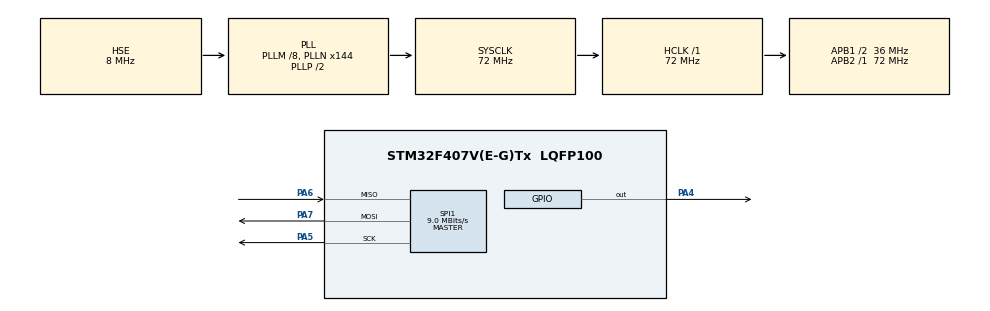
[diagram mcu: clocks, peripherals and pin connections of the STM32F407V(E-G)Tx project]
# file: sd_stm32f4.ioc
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FATFS._MAX_SS=4096
FATFS._USE_LFN=1
Mcu.Family=STM32F4
Mcu.Name=STM32F407V(E-G)Tx
Mcu.Package=LQFP100
NVIC.PriorityGroup=NVIC_PRIORITYGROUP_4
PA4.Signal=GPIO_Output
PA5.Mode=Full_Duplex_Master
PA5.Signal=SPI1_SCK
PA6.Mode=Full_Duplex_Master
PA6.Signal=SPI1_MISO
PA7.Mode=Full_Duplex_Master
PA7.Signal=SPI1_MOSI
PH0-OSC_IN.Mode=HSE-External-Oscillator
PH0-OSC_IN.Signal=RCC_OSC_IN
PH1-OSC_OUT.Mode=HSE-External-Oscillator
PH1-OSC_OUT.Signal=RCC_OSC_OUT
ProjectManager.HeapSize=0x200
ProjectManager.StackSize=0x400
ProjectManager.TargetToolchain=MDK-ARM V5
RCC.48MHZClocksFreq_Value=36000000
RCC.AHBFreq_Value=72000000
RCC.APB1CLKDivider=RCC_HCLK_DIV2
RCC.APB1Freq_Value=36000000
RCC.APB1TimFreq_Value=72000000
RCC.APB2Freq_Value=72000000
RCC.APB2TimFreq_Value=72000000
RCC.CortexFreq_Value=72000000
RCC.HCLKFreq_Value=72000000
RCC.HSE_VALUE=8000000
RCC.HSI_VALUE=16000000
RCC.LSE_VALUE=32768
RCC.PLLM=8
RCC.PLLN=144
RCC.PLLSourceVirtual=RCC_PLLSOURCE_HSE
RCC.SYSCLKFreq_VALUE=72000000
RCC.SYSCLKSource=RCC_SYSCLKSOURCE_PLLCLK
RCC.VCOOutputFreq_Value=144000000
SPI1.BaudRatePrescaler=SPI_BAUDRATEPRESCALER_8
SPI1.CalculateBaudRate=9.0 MBits/s
SPI1.Direction=SPI_DIRECTION_2LINES
SPI1.Mode=SPI_MODE_MASTER
SPI1.VirtualType=VM_MASTER
VP_FATFS_VS_Generic.Mode=User_defined
board=test_sd_stm32f4

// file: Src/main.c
/**
  ******************************************************************************
  * @file           : main.c
  * @brief          : Main program body
  ******************************************************************************
  * This notice applies to any and all portions of this file
  * that are not between comment pairs USER CODE BEGIN and
  * USER CODE END. Other portions of this file, whether
  * inserted by the user or by software development tools
  * are owned by their respective copyright owners.
  *
  * Copyright (c) 2018 STMicroelectronics International N.V.
  * All rights reserved.
  *
  * Redistribution and use in source and binary forms, with or without
  * modification, are permitted, provided that the following conditions are met:
  *
  * 1. Redistribution of source code must retain the above copyright notice,
  *    this list of conditions and the following disclaimer.
  * 2. Redistributions in binary form must reproduce the above copyright notice,
  *    this list of conditions and the following disclaimer in the documentation
  *    and/or other materials provided with the distribution.
  * 3. Neither the name of STMicroelectronics nor the names of other
  *    contributors to this software may be used to endorse or promote products
  *    derived from this software without specific written permission.
  * 4. This software, including modifications and/or derivative works of this
  *    software, must execute solely and exclusively on microcontroller or
  *    microprocessor devices manufactured by or for STMicroelectronics.
  * 5. Redistribution and use of this software other than as permitted under
  *    this license is void and will automatically terminate your rights under
  *    this license.
  *
  * THIS SOFTWARE IS PROVIDED BY STMICROELECTRONICS AND CONTRIBUTORS "AS IS"
  * AND ANY EXPRESS, IMPLIED OR STATUTORY WARRANTIES, INCLUDING, BUT NOT
  * LIMITED TO, THE IMPLIED WARRANTIES OF MERCHANTABILITY, FITNESS FOR A
  * PARTICULAR PURPOSE AND NON-INFRINGEMENT OF THIRD PARTY INTELLECTUAL PROPERTY
  * RIGHTS ARE DISCLAIMED TO THE FULLEST EXTENT PERMITTED BY LAW. IN NO EVENT
  * SHALL STMICROELECTRONICS OR CONTRIBUTORS BE LIABLE FOR ANY DIRECT, INDIRECT,
  * INCIDENTAL, SPECIAL, EXEMPLARY, OR CONSEQUENTIAL DAMAGES (INCLUDING, BUT NOT
  * LIMITED TO, PROCUREMENT OF SUBSTITUTE GOODS OR SERVICES; LOSS OF USE, DATA,
  * OR PROFITS; OR BUSINESS INTERRUPTION) HOWEVER CAUSED AND ON ANY THEORY OF
  * LIABILITY, WHETHER IN CONTRACT, STRICT LIABILITY, OR TORT (INCLUDING
  * NEGLIGENCE OR OTHERWISE) ARISING IN ANY WAY OUT OF THE USE OF THIS SOFTWARE,
  * EVEN IF ADVISED OF THE POSSIBILITY OF SUCH DAMAGE.
  *
  ******************************************************************************
  */
#include "main.h"
#include "stm32f4xx_hal.h"
#include "fatfs.h"

SPI_HandleTypeDef hspi1;

FATFS fs;
FATFS *pfs;
FIL fil;
FRESULT fres;
DWORD fre_clust;
uint32_t total, free1;
char buffer[100];

/* USER CODE BEGIN PV */
/* Private variables ---------------------------------------------------------*/

/* USER CODE END PV */

void SystemClock_Config(void);
static void MX_GPIO_Init(void);
static void MX_SPI1_Init(void);

/* USER CODE BEGIN PFP */
/* Private function prototypes -----------------------------------------------*/

/* USER CODE END PFP */

int main(void)
{

  /* MCU Configuration----------------------------------------------------------*/

  /* Reset of all peripherals, Initializes the Flash interface and the Systick. */
  HAL_Init();

  /* Configure the system clock */
  SystemClock_Config();

  /* Initialize all configured peripherals */
  MX_GPIO_Init();
  MX_FATFS_Init();
  MX_SPI1_Init();
  /* USER CODE BEGIN 2 */
  //HAL_GPIO_WritePin(GPIOA,GPIO_PIN_4,GPIO_PIN_SET);
  //HAL_Delay(10);

	/* USER CODE END 2 */
  /* Mount SD Card */
  if(f_mount(&fs, "", 0) != FR_OK)
    _Error_Handler(__FILE__, __LINE__);

  /* Open file to write */
  if(f_open(&fil, "second.py", FA_OPEN_ALWAYS | FA_READ | FA_WRITE) != FR_OK)
    _Error_Handler(__FILE__, __LINE__);

  /* Check free space */
  if(f_getfree("", &fre_clust, &pfs) != FR_OK)
    _Error_Handler(__FILE__, __LINE__);

  total = (uint32_t)((pfs->n_fatent - 2) * pfs->csize * 0.5);
  free1 = (uint32_t)(fre_clust * pfs->csize * 0.5);

  /* Free space is less than 1kb */
  if(free1 < 1)
    _Error_Handler(__FILE__, __LINE__);

  /* Writing text */
  f_puts("SAKET\n", &fil);
  f_puts("KIRANGE!!!", &fil);

  /* Close file */
  if(f_close(&fil) != FR_OK)
    _Error_Handler(__FILE__, __LINE__);

  /* Open file to read */
  if(f_open(&fil, "second.py", FA_READ) != FR_OK)
    _Error_Handler(__FILE__, __LINE__);

  while(f_gets(buffer, sizeof(buffer), &fil))
  {
    //printf("%s", buffer);
  }

  /* Close file */
  if(f_close(&fil) != FR_OK)
    _Error_Handler(__FILE__, __LINE__);

  /* Unmount SDCARD */
  if(f_mount(NULL, "", 1) != FR_OK)
    _Error_Handler(__FILE__, __LINE__);

  /* Infinite loop */
  while (1)
  {

  }

}

void SystemClock_Config(void)
{

  RCC_OscInitTypeDef RCC_OscInitStruct;
  RCC_ClkInitTypeDef RCC_ClkInitStruct;

    /**Configure the main internal regulator output voltage
    */
  __HAL_RCC_PWR_CLK_ENABLE();

  __HAL_PWR_VOLTAGESCALING_CONFIG(PWR_REGULATOR_VOLTAGE_SCALE1);

    /**Initializes the CPU, AHB and APB busses clocks
    */
  RCC_OscInitStruct.OscillatorType = RCC_OSCILLATORTYPE_HSE;
  RCC_OscInitStruct.HSEState = RCC_HSE_ON;
  RCC_OscInitStruct.PLL.PLLState = RCC_PLL_ON;
  RCC_OscInitStruct.PLL.PLLSource = RCC_PLLSOURCE_HSE;
  RCC_OscInitStruct.PLL.PLLM = 8;
  RCC_OscInitStruct.PLL.PLLN = 144;
  RCC_OscInitStruct.PLL.PLLP = RCC_PLLP_DIV2;
  RCC_OscInitStruct.PLL.PLLQ = 4;
  if (HAL_RCC_OscConfig(&RCC_OscInitStruct) != HAL_OK)
  {
    _Error_Handler(__FILE__, __LINE__);
  }

    /**Initializes the CPU, AHB and APB busses clocks
    */
  RCC_ClkInitStruct.ClockType = RCC_CLOCKTYPE_HCLK|RCC_CLOCKTYPE_SYSCLK
                              |RCC_CLOCKTYPE_PCLK1|RCC_CLOCKTYPE_PCLK2;
  RCC_ClkInitStruct.SYSCLKSource = RCC_SYSCLKSOURCE_PLLCLK;
  RCC_ClkInitStruct.AHBCLKDivider = RCC_SYSCLK_DIV1;
  RCC_ClkInitStruct.APB1CLKDivider = RCC_HCLK_DIV2;
  RCC_ClkInitStruct.APB2CLKDivider = RCC_HCLK_DIV1;

  if (HAL_RCC_ClockConfig(&RCC_ClkInitStruct, FLASH_LATENCY_2) != HAL_OK)
  {
    _Error_Handler(__FILE__, __LINE__);
  }

    /**Configure the Systick interrupt time
    */
  HAL_SYSTICK_Config(HAL_RCC_GetHCLKFreq()/1000);

    /**Configure the Systick
    */
  HAL_SYSTICK_CLKSourceConfig(SYSTICK_CLKSOURCE_HCLK);

  /* SysTick_IRQn interrupt configuration */
  HAL_NVIC_SetPriority(SysTick_IRQn, 0, 0);
}

/* SPI1 init function */
static void MX_SPI1_Init(void)
{

  /* SPI1 parameter configuration*/
  hspi1.Instance = SPI1;
  hspi1.Init.Mode = SPI_MODE_MASTER;
  hspi1.Init.Direction = SPI_DIRECTION_2LINES;
  hspi1.Init.DataSize = SPI_DATASIZE_8BIT;
  hspi1.Init.CLKPolarity = SPI_POLARITY_LOW;
  hspi1.Init.CLKPhase = SPI_PHASE_1EDGE;
  hspi1.Init.NSS = SPI_NSS_SOFT;
  hspi1.Init.BaudRatePrescaler = SPI_BAUDRATEPRESCALER_8;
  hspi1.Init.FirstBit = SPI_FIRSTBIT_MSB;
  hspi1.Init.TIMode = SPI_TIMODE_DISABLE;
  hspi1.Init.CRCCalculation = SPI_CRCCALCULATION_DISABLE;
  hspi1.Init.CRCPolynomial = 10;
  if (HAL_SPI_Init(&hspi1) != HAL_OK)
  {
    _Error_Handler(__FILE__, __LINE__);
  }

}

/** Configure pins as
        * Analog
        * Input
        * Output
        * EVENT_OUT
        * EXTI
*/
static void MX_GPIO_Init(void)
{

  GPIO_InitTypeDef GPIO_InitStruct;

  /* GPIO Ports Clock Enable */
  __HAL_RCC_GPIOH_CLK_ENABLE();
  __HAL_RCC_GPIOA_CLK_ENABLE();

  /*Configure GPIO pin Output Level */
  HAL_GPIO_WritePin(GPIOA, GPIO_PIN_4, GPIO_PIN_SET);

  /*Configure GPIO pin : PA4 */
  GPIO_InitStruct.Pin = GPIO_PIN_4;
  GPIO_InitStruct.Mode = GPIO_MODE_OUTPUT_PP;
  GPIO_InitStruct.Pull = GPIO_NOPULL;
  GPIO_InitStruct.Speed = GPIO_SPEED_FREQ_LOW;
  HAL_GPIO_Init(GPIOA, &GPIO_InitStruct);

}

void _Error_Handler(char *file, int line)
{
  while(1)
  {
  }
}

/************************ (C) COPYRIGHT STMicroelectronics *****END OF FILE****/
